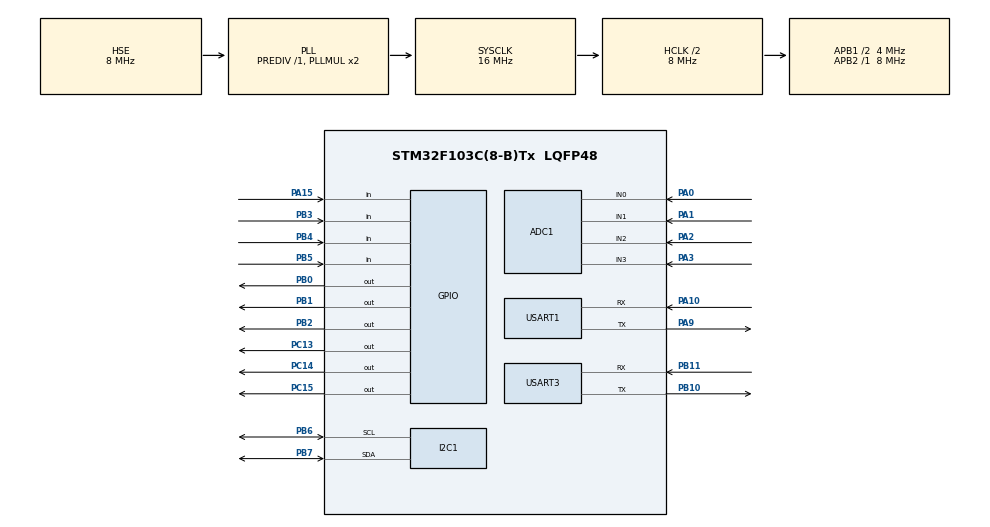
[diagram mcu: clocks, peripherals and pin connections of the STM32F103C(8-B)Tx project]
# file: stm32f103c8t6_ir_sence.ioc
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ADC1.Channel-2\#ChannelRegularConversion=ADC_CHANNEL_0
ADC1.Channel-3\#ChannelRegularConversion=ADC_CHANNEL_1
ADC1.Channel-4\#ChannelRegularConversion=ADC_CHANNEL_2
ADC1.Channel-5\#ChannelRegularConversion=ADC_CHANNEL_3
ADC1.ContinuousConvMode=ENABLE
ADC1.NbrOfConversion=4
ADC1.NbrOfConversionFlag=1
ADC1.Rank-2\#ChannelRegularConversion=1
ADC1.Rank-3\#ChannelRegularConversion=2
ADC1.Rank-4\#ChannelRegularConversion=3
ADC1.Rank-5\#ChannelRegularConversion=4
ADC1.SamplingTime-2\#ChannelRegularConversion=ADC_SAMPLETIME_239CYCLES_5
ADC1.SamplingTime-3\#ChannelRegularConversion=ADC_SAMPLETIME_239CYCLES_5
ADC1.SamplingTime-4\#ChannelRegularConversion=ADC_SAMPLETIME_239CYCLES_5
ADC1.SamplingTime-5\#ChannelRegularConversion=ADC_SAMPLETIME_239CYCLES_5
ADC1.master=1
Dma.ADC1.0.Direction=DMA_PERIPH_TO_MEMORY
Dma.ADC1.0.Instance=DMA1_Channel1
Dma.ADC1.0.MemDataAlignment=DMA_MDATAALIGN_HALFWORD
Dma.ADC1.0.MemInc=DMA_MINC_ENABLE
Dma.ADC1.0.Mode=DMA_CIRCULAR
Dma.ADC1.0.PeriphDataAlignment=DMA_PDATAALIGN_HALFWORD
Dma.ADC1.0.PeriphInc=DMA_PINC_DISABLE
Dma.ADC1.0.Priority=DMA_PRIORITY_LOW
Dma.Request0=ADC1
Mcu.Family=STM32F1
Mcu.Name=STM32F103C(8-B)Tx
Mcu.Package=LQFP48
NVIC.DMA1_Channel1_IRQn=true\:0\:0\:false\:false\:true\:false\:true\:true
NVIC.PriorityGroup=NVIC_PRIORITYGROUP_4
NVIC.USART3_IRQn=true\:2\:0\:true\:false\:true\:true\:true\:true
PA0-WKUP.Signal=ADCx_IN0
PA1.Signal=ADCx_IN1
PA10.Mode=Asynchronous
PA10.Signal=USART1_RX
PA13.Mode=Serial_Wire
PA13.Signal=SYS_JTMS-SWDIO
PA14.Mode=Serial_Wire
PA14.Signal=SYS_JTCK-SWCLK
PA15.Signal=GPIO_Input
PA2.Signal=ADCx_IN2
PA3.Signal=ADCx_IN3
PA9.Mode=Asynchronous
PA9.Signal=USART1_TX
PB0.Signal=GPIO_Output
PB1.Signal=GPIO_Output
PB10.Mode=Asynchronous
PB10.Signal=USART3_TX
PB11.Mode=Asynchronous
PB11.Signal=USART3_RX
PB2.Signal=GPIO_Output
PB3.Signal=GPIO_Input
PB4.Signal=GPIO_Input
PB5.Signal=GPIO_Input
PB6.Mode=I2C
PB6.Signal=I2C1_SCL
PB7.Mode=I2C
PB7.Signal=I2C1_SDA
PC13-TAMPER-RTC.Signal=GPIO_Output
PC14-OSC32_IN.Signal=GPIO_Output
PC15-OSC32_OUT.Signal=GPIO_Output
PD0-OSC_IN.Mode=HSE-External-Oscillator
PD0-OSC_IN.Signal=RCC_OSC_IN
PD1-OSC_OUT.Mode=HSE-External-Oscillator
PD1-OSC_OUT.Signal=RCC_OSC_OUT
ProjectManager.HeapSize=0x200
ProjectManager.StackSize=0x400
ProjectManager.TargetToolchain=STM32CubeIDE
RCC.ADCPresc=RCC_ADCPCLK2_DIV8
RCC.AHBCLKDivider=RCC_SYSCLK_DIV2
RCC.AHBFreq_Value=8000000
RCC.APB1CLKDivider=RCC_HCLK_DIV2
RCC.APB1Freq_Value=4000000
RCC.APB1TimFreq_Value=8000000
RCC.APB2Freq_Value=8000000
RCC.APB2TimFreq_Value=8000000
RCC.HCLKFreq_Value=8000000
RCC.PLLSourceVirtual=RCC_PLLSOURCE_HSE
RCC.SYSCLKFreq_VALUE=16000000
RCC.SYSCLKSource=RCC_SYSCLKSOURCE_PLLCLK
RCC.USBFreq_Value=16000000
SH.ADCx_IN0.0=ADC1_IN0,IN0
SH.ADCx_IN1.0=ADC1_IN1,IN1
SH.ADCx_IN2.0=ADC1_IN2,IN2
SH.ADCx_IN3.0=ADC1_IN3,IN3
USART1.VirtualMode=VM_ASYNC
USART3.VirtualMode=VM_ASYNC
board=custom

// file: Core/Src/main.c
/* USER CODE BEGIN Header */
/**
  ******************************************************************************
  * @file           : main.c
  * @brief          : Main program body
  ******************************************************************************
  * @attention
  *
  * Copyright (c) 2025 STMicroelectronics.
  * All rights reserved.
  *
  * This software is licensed under terms that can be found in the LICENSE file
  * in the root directory of this software component.
  * If no LICENSE file comes with this software, it is provided AS-IS.
  *
  ******************************************************************************
  */
/* USER CODE END Header */
#include "main.h"
#include "drv_adc.h"
#include "uart_drv.h"
#include "mgr.h"
#include"drive_time.h"

ADC_HandleTypeDef hadc1;
DMA_HandleTypeDef hdma_adc1;

I2C_HandleTypeDef hi2c1;

UART_HandleTypeDef huart1;
UART_HandleTypeDef huart3;

void SystemClock_Config(void);
static void MX_GPIO_Init(void);
static void MX_DMA_Init(void);
static void MX_ADC1_Init(void);
static void MX_I2C1_Init(void);
static void MX_USART1_UART_Init(void);
static void MX_USART3_UART_Init(void);

int main(void)
{

	/* MCU Configuration--------------------------------------------------------*/

	/* Reset of all peripherals, Initializes the Flash interface and the Systick. */
	HAL_Init();

	/* Configure the system clock */
	SystemClock_Config();

	/* Initialize all configured peripherals */
	MX_GPIO_Init();
	MX_DMA_Init();
	MX_ADC1_Init();

	ADC1_Calibration();

	MX_I2C1_Init();
	MX_USART1_UART_Init();
	MX_USART3_UART_Init();
	/* USER CODE BEGIN 2 */
	Timer2_Init();
	reset_timer();
	Delay_SetTimer(TID_TIMER_1ms,1);
	Delay_SetTimer(TID_COUNT_10ms,10);
	Delay_SetTimer(TID_TIMER_1000ms,1000);
	ADC_Init_main();
  /* USER CODE END 2 */

  /* Infinite loop */
  while (1)
  {
	  if(Delay_GetTimer(TID_TIMER_1ms))
	  {
		  Task_Ir_Run();
	  }
	  if(Delay_GetTimer(TID_TIMER_1000ms))
	  {
		Task_uart();
	  }
  }
}

void SystemClock_Config(void)
{
  RCC_OscInitTypeDef RCC_OscInitStruct = {0};
  RCC_ClkInitTypeDef RCC_ClkInitStruct = {0};
  RCC_PeriphCLKInitTypeDef PeriphClkInit = {0};

  /** Initializes the RCC Oscillators according to the specified parameters
  * in the RCC_OscInitTypeDef structure.
  */
  RCC_OscInitStruct.OscillatorType = RCC_OSCILLATORTYPE_HSE;
  RCC_OscInitStruct.HSEState = RCC_HSE_ON;
  RCC_OscInitStruct.HSEPredivValue = RCC_HSE_PREDIV_DIV1;
  RCC_OscInitStruct.HSIState = RCC_HSI_ON;
  RCC_OscInitStruct.PLL.PLLState = RCC_PLL_ON;
  RCC_OscInitStruct.PLL.PLLSource = RCC_PLLSOURCE_HSE;
  RCC_OscInitStruct.PLL.PLLMUL = RCC_PLL_MUL2;
  if (HAL_RCC_OscConfig(&RCC_OscInitStruct) != HAL_OK)
  {
    Error_Handler();
  }

  /** Initializes the CPU, AHB and APB buses clocks
  */
  RCC_ClkInitStruct.ClockType = RCC_CLOCKTYPE_HCLK|RCC_CLOCKTYPE_SYSCLK
                              |RCC_CLOCKTYPE_PCLK1|RCC_CLOCKTYPE_PCLK2;
  RCC_ClkInitStruct.SYSCLKSource = RCC_SYSCLKSOURCE_PLLCLK;
  RCC_ClkInitStruct.AHBCLKDivider = RCC_SYSCLK_DIV2;
  RCC_ClkInitStruct.APB1CLKDivider = RCC_HCLK_DIV2;
  RCC_ClkInitStruct.APB2CLKDivider = RCC_HCLK_DIV1;

  if (HAL_RCC_ClockConfig(&RCC_ClkInitStruct, FLASH_LATENCY_0) != HAL_OK)
  {
    Error_Handler();
  }
  PeriphClkInit.PeriphClockSelection = RCC_PERIPHCLK_ADC;
  PeriphClkInit.AdcClockSelection = RCC_ADCPCLK2_DIV8;
  if (HAL_RCCEx_PeriphCLKConfig(&PeriphClkInit) != HAL_OK)
  {
    Error_Handler();
  }
}

static void MX_ADC1_Init(void)
{

  ADC_ChannelConfTypeDef sConfig = {0};

  /** Common config
  */
  hadc1.Instance = ADC1;
  hadc1.Init.ScanConvMode = ADC_SCAN_ENABLE;
  hadc1.Init.ContinuousConvMode = ENABLE;
  hadc1.Init.DiscontinuousConvMode = DISABLE;
  hadc1.Init.ExternalTrigConv = ADC_SOFTWARE_START;
  hadc1.Init.DataAlign = ADC_DATAALIGN_RIGHT;
  hadc1.Init.NbrOfConversion = 4;
  if (HAL_ADC_Init(&hadc1) != HAL_OK)
  {
    Error_Handler();
  }

  /** Configure Regular Channel
  */
  sConfig.Channel = ADC_CHANNEL_0;
  sConfig.Rank = ADC_REGULAR_RANK_1;
  sConfig.SamplingTime = ADC_SAMPLETIME_239CYCLES_5;
  if (HAL_ADC_ConfigChannel(&hadc1, &sConfig) != HAL_OK)
  {
    Error_Handler();
  }

  /** Configure Regular Channel
  */
  sConfig.Channel = ADC_CHANNEL_1;
  sConfig.Rank = ADC_REGULAR_RANK_2;
  if (HAL_ADC_ConfigChannel(&hadc1, &sConfig) != HAL_OK)
  {
    Error_Handler();
  }

  /** Configure Regular Channel
  */
  sConfig.Channel = ADC_CHANNEL_2;
  sConfig.Rank = ADC_REGULAR_RANK_3;
  if (HAL_ADC_ConfigChannel(&hadc1, &sConfig) != HAL_OK)
  {
    Error_Handler();
  }

  /** Configure Regular Channel
  */
  sConfig.Channel = ADC_CHANNEL_3;
  sConfig.Rank = ADC_REGULAR_RANK_4;
  if (HAL_ADC_ConfigChannel(&hadc1, &sConfig) != HAL_OK)
  {
    Error_Handler();
  }

}

static void MX_I2C1_Init(void)
{

  hi2c1.Instance = I2C1;
  hi2c1.Init.ClockSpeed = 100000;
  hi2c1.Init.DutyCycle = I2C_DUTYCYCLE_2;
  hi2c1.Init.OwnAddress1 = 0;
  hi2c1.Init.AddressingMode = I2C_ADDRESSINGMODE_7BIT;
  hi2c1.Init.DualAddressMode = I2C_DUALADDRESS_DISABLE;
  hi2c1.Init.OwnAddress2 = 0;
  hi2c1.Init.GeneralCallMode = I2C_GENERALCALL_DISABLE;
  hi2c1.Init.NoStretchMode = I2C_NOSTRETCH_DISABLE;
  if (HAL_I2C_Init(&hi2c1) != HAL_OK)
  {
    Error_Handler();
  }

}

static void MX_USART1_UART_Init(void)
{

  huart1.Instance = USART1;
  huart1.Init.BaudRate = 115200;
  huart1.Init.WordLength = UART_WORDLENGTH_8B;
  huart1.Init.StopBits = UART_STOPBITS_1;
  huart1.Init.Parity = UART_PARITY_NONE;
  huart1.Init.Mode = UART_MODE_TX_RX;
  huart1.Init.HwFlowCtl = UART_HWCONTROL_NONE;
  huart1.Init.OverSampling = UART_OVERSAMPLING_16;
  if (HAL_UART_Init(&huart1) != HAL_OK)
  {
    Error_Handler();
  }

}

static void MX_USART3_UART_Init(void)
{

  huart3.Instance = USART3;
  huart3.Init.BaudRate = 115200;
  huart3.Init.WordLength = UART_WORDLENGTH_8B;
  huart3.Init.StopBits = UART_STOPBITS_1;
  huart3.Init.Parity = UART_PARITY_NONE;
  huart3.Init.Mode = UART_MODE_TX_RX;
  huart3.Init.HwFlowCtl = UART_HWCONTROL_NONE;
  huart3.Init.OverSampling = UART_OVERSAMPLING_16;
  if (HAL_UART_Init(&huart3) != HAL_OK)
  {
    Error_Handler();
  }

}

static void MX_DMA_Init(void)
{

  /* DMA controller clock enable */
  __HAL_RCC_DMA1_CLK_ENABLE();

  /* DMA interrupt init */
  /* DMA1_Channel1_IRQn interrupt configuration */
  HAL_NVIC_SetPriority(DMA1_Channel1_IRQn, 0, 0);
  HAL_NVIC_EnableIRQ(DMA1_Channel1_IRQn);

}

static void MX_GPIO_Init(void)
{
  GPIO_InitTypeDef GPIO_InitStruct = {0};

  /* GPIO Ports Clock Enable */
  __HAL_RCC_GPIOC_CLK_ENABLE();
  __HAL_RCC_GPIOD_CLK_ENABLE();
  __HAL_RCC_GPIOA_CLK_ENABLE();
  __HAL_RCC_GPIOB_CLK_ENABLE();

  /*Configure GPIO pin Output Level */
  HAL_GPIO_WritePin(GPIOC, GPIO_PIN_13|GPIO_PIN_14|GPIO_PIN_15, GPIO_PIN_RESET);

  /*Configure GPIO pin Output Level */
  HAL_GPIO_WritePin(GPIOB, GPIO_PIN_0|GPIO_PIN_1|GPIO_PIN_2, GPIO_PIN_RESET);

  /*Configure GPIO pins : PC13 PC14 PC15 */
  GPIO_InitStruct.Pin = GPIO_PIN_13|GPIO_PIN_14|GPIO_PIN_15;
  GPIO_InitStruct.Mode = GPIO_MODE_OUTPUT_PP;
  GPIO_InitStruct.Pull = GPIO_NOPULL;
  GPIO_InitStruct.Speed = GPIO_SPEED_FREQ_LOW;
  HAL_GPIO_Init(GPIOC, &GPIO_InitStruct);

  /*Configure GPIO pins : PB0 PB1 PB2 */
  GPIO_InitStruct.Pin = GPIO_PIN_0|GPIO_PIN_1|GPIO_PIN_2;
  GPIO_InitStruct.Mode = GPIO_MODE_OUTPUT_PP;
  GPIO_InitStruct.Pull = GPIO_NOPULL;
  GPIO_InitStruct.Speed = GPIO_SPEED_FREQ_LOW;
  HAL_GPIO_Init(GPIOB, &GPIO_InitStruct);

  /*Configure GPIO pin : PA15 */
  GPIO_InitStruct.Pin = GPIO_PIN_15;
  GPIO_InitStruct.Mode = GPIO_MODE_INPUT;
  GPIO_InitStruct.Pull = GPIO_NOPULL;
  HAL_GPIO_Init(GPIOA, &GPIO_InitStruct);

  /*Configure GPIO pins : PB3 PB4 PB5 */
  GPIO_InitStruct.Pin = GPIO_PIN_3|GPIO_PIN_4|GPIO_PIN_5;
  GPIO_InitStruct.Mode = GPIO_MODE_INPUT;
  GPIO_InitStruct.Pull = GPIO_NOPULL;
  HAL_GPIO_Init(GPIOB, &GPIO_InitStruct);

}

void Error_Handler(void)
{
  __disable_irq();
  while (1)
  {
  }
}
